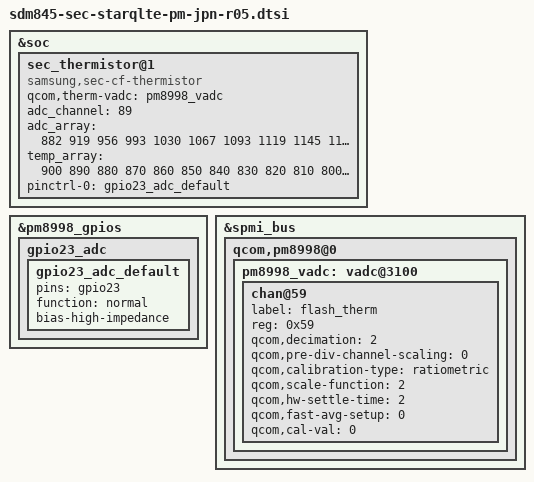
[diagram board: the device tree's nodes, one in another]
/* Copyright (c) 2014, The Linux Foundation. All rights reserved.
 *
 * This program is free software; you can redistribute it and/or modify
 * it under the terms of the GNU General Public License version 2 and
 * only version 2 as published by the Free Software Foundation.
 *
 * This program is distributed in the hope that it will be useful,
 * but WITHOUT ANY WARRANTY; without even the implied warranty of
 * MERCHANTABILITY or FITNESS FOR A PARTICULAR PURPOSE.  See the
 * GNU General Public License for more details.
 */

&soc {
	sec_thermistor@1 {
		compatible = "samsung,sec-cf-thermistor";
		qcom,therm-vadc = <&pm8998_vadc>;
		status = "okay";
		adc_channel = <89>;
		adc_array = <882 919 956 993 1030 1067 1093 1119 1145 1171
				1195 1222 1249 1276 1303 1332 1363 1394 1425 1456
				1489 1534 1579 1624 1669 1712 1912 2112 2312 2512
				2712 2821 2930 3039 3148 3258 3377 3496 3615 3734
				3852 3986 4120 4254 4388 4521 4665 4809 4953 5097
				5239 5403 5567 5731 5895 6059 6203 6347 6491 6635
				6779 7032 7285 7538 7791 8045 8192 8339 8486 8633
				8779 8979 9179 9379 9579 9778 9962 10146 10330 10514
				10699 10843 10987 11131 11275 11417 11520 11623 11726 11829
				11932 12150 12368 12586 12804 13023 13155 13287 13419 13551
				13684 13800 13916 14032 14148 14266 14361 14456 14551 14646
				14739>;

		temp_array = <900 890 880 870 860 850 840 830 820 810
				800 790 780 770 760 750 740 730 720 710
				700 690 680 670 660 650 640 630 620 610
				600 590 580 570 560 550 540 530 520 510
				500 490 480 470 460 450 440 430 420 410
				400 390 380 370 360 350 340 330 320 310
				300 290 280 270 260 250 240 230 220 210
				200 190 180 170 160 150 140 130 120 110
				100 90 80 70 60 50 40 30 20 10
				0
				(-10) (-20) (-30) (-40) (-50) (-60) (-70) (-80) (-90) (-100)
				(-110)(-120)(-130)(-140)(-150)(-160)(-170)(-180)(-190) (-200)>;
	};

	sec_thermistor@1 {
		pinctrl-names = "default";
		pinctrl-0 = <&gpio23_adc_default>;
	};
};

&pm8998_gpios {
	gpio23_adc {
		gpio23_adc_default: gpio23_adc_default {
			pins = "gpio23"; /* GPIO 23 */
			function = "normal"; /* normal */
			bias-high-impedance; /* DISABLE GPIO23 for ADC*/
		};
	};
};


&spmi_bus {
	qcom,pm8998@0 {
        pm8998_vadc: vadc@3100 {
            chan@59 {
                label = "flash_therm";
                reg = <0x59>;
                qcom,decimation = <2>;
                qcom,pre-div-channel-scaling = <0>;
                qcom,calibration-type = "ratiometric";
                qcom,scale-function = <2>;
                qcom,hw-settle-time = <2>;
                qcom,fast-avg-setup = <0>;
                qcom,cal-val = <0>;
            };
        };
    };
};
